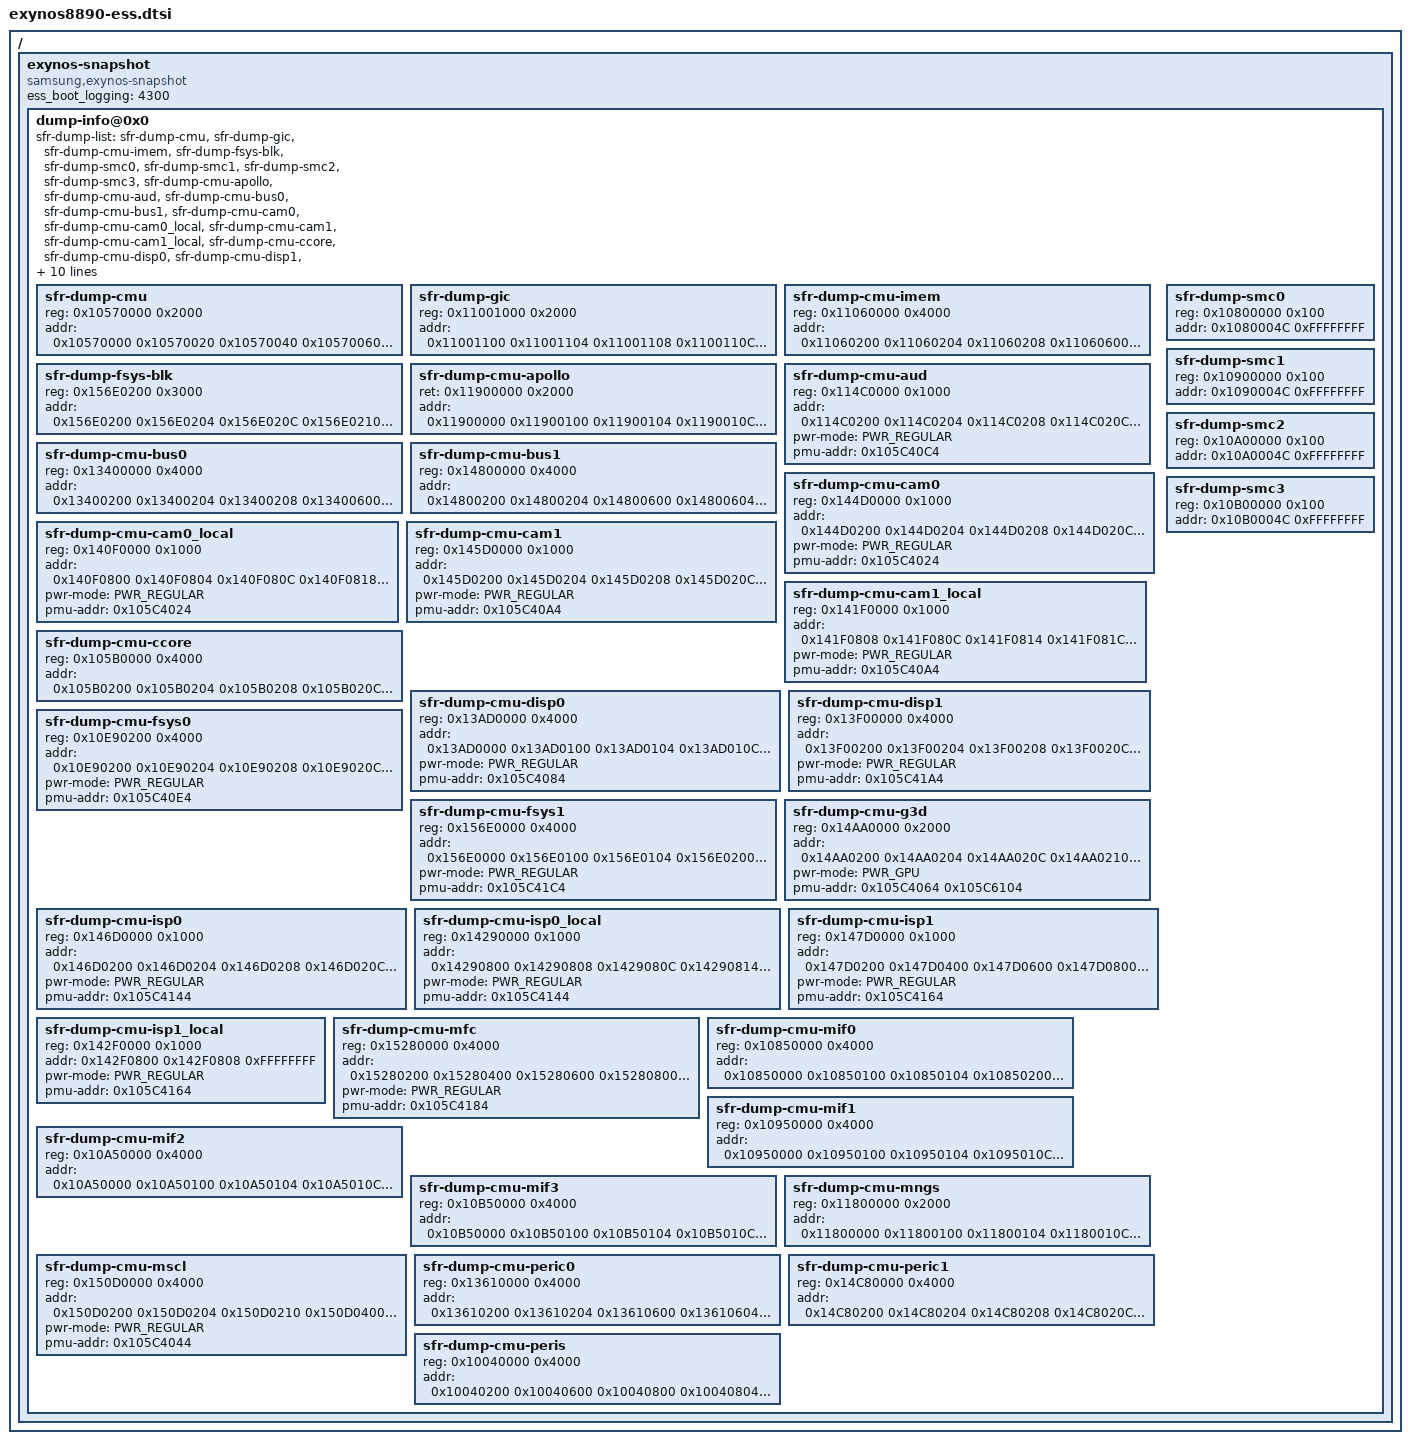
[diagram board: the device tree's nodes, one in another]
/*
 * SAMSUNG EXYNOS8890 SoC device tree source
 *
 * Copyright (c) 2015 Samsung Electronics Co., Ltd.
 *		http://www.samsung.com
 *
 * SAMSUNG EXYNOS8890 SoC device nodes are listed in this file.
 * EXYNOS8890 based board files can include this file and provide
 * values for board specfic bindings.
 *
 * This program is free software; you can redistribute it and/or modify
 * it under the terms of the GNU General Public License version 2 as
 * published by the Free Software Foundation.
 */

/ {
	exynos-snapshot {
		#define PWR_NONE	0
		#define PWR_REGULAR	1
		#define PWR_GPU		2

		compatible = "samsung,exynos-snapshot";
		ess_boot_logging = <4300>;
		dump-info@0x0 {
			sfr-dump-list = "sfr-dump-cmu", "sfr-dump-gic", "sfr-dump-cmu-imem","sfr-dump-fsys-blk",
					"sfr-dump-smc0", "sfr-dump-smc1", "sfr-dump-smc2", "sfr-dump-smc3",
					"sfr-dump-cmu-apollo", "sfr-dump-cmu-aud", "sfr-dump-cmu-bus0", "sfr-dump-cmu-bus1", "sfr-dump-cmu-cam0",
					"sfr-dump-cmu-cam0_local", "sfr-dump-cmu-cam1", "sfr-dump-cmu-cam1_local", "sfr-dump-cmu-ccore", "sfr-dump-cmu-disp0",
					"sfr-dump-cmu-disp1", "sfr-dump-cmu-fsys0", "sfr-dump-cmu-fsys1", "sfr-dump-cmu-g3d", "sfr-dump-cmu-isp0",
					"sfr-dump-cmu-isp0_local", "sfr-dump-cmu-isp1", "sfr-dump-cmu-isp1_local", "sfr-dump-cmu-mfc", "sfr-dump-cmu-mif0",
					"sfr-dump-cmu-mif1", "sfr-dump-cmu-mif2", "sfr-dump-cmu-mif3", "sfr-dump-cmu-mngs", "sfr-dump-cmu-mscl",
					"sfr-dump-cmu-peric0", "sfr-dump-cmu-peric1", "sfr-dump-cmu-peris";
			#address-cells = <1>;
			#size-cells = <1>;

			pmu-regs = <0x105C4000 0x4000>;

			sfr-dump-cmu {
					reg = <0x10570000 0x2000>;
					addr = <0x10570000 0x10570020 0x10570040 0x10570060 0x10570080 0x105700A0 0x105700C0
						0x105700E0 0x10570100 0x10570104 0x1057010C 0x10570120 0x10570124 0x1057012C
						0x10570140 0x10570144 0x1057014C 0x10570160 0x10570164 0x1057016C 0x10570180
						0x10570184 0x1057018C 0x105701A0 0x105701A4 0x105701AC 0x105701C0 0x105701C4
						0x105701C8 0x105701E0 0x105701E4 0x105701EC 0x10570200 0x10570204 0x10570208
						0x1057020C 0x10570210 0x10570214 0x10570218 0x1057021C 0x10570220 0x10570224
						0x10570228 0x1057022C 0x10570230 0x10570234 0x10570240 0x10570244 0x10570248
						0x1057024C 0x10570250 0x10570254 0x10570258 0x1057025C 0x10570260 0x10570264
						0x10570268 0x1057026C 0x10570270 0x10570274 0x10570278 0x1057027C 0x10570280
						0x10570284 0x10570288 0x1057028C 0x10570290 0x10570294 0x10570298 0x1057029C
						0x105702A0 0x105702A4 0x105702A8 0x105702AC 0x105702B0 0x105702B4 0x105702B8
						0x105702BC 0x105702C0 0x105702C4 0x105702C8 0x105702CC 0x105702D0 0x105702D4
						0x105702D8 0x105702DC 0x105702E0 0x105702E4 0x105702E8 0x105702EC 0x105702F0
						0x105702F4 0x105702F8 0x105702FC 0x10570300 0x10570304 0x10570308 0x1057030C
						0x10570310 0x10570314 0x10570318 0x1057031C 0x10570320 0x10570324 0x10570328
						0x1057032C 0x10570330 0x10570334 0x10570338 0x1057033C 0x10570340 0x10570344
						0x10570348 0x1057034C 0x10570350 0x10570354 0x10570358 0x1057035C 0x10570360
						0x10570364 0x10570368 0x1057036C 0x10570370 0x10570374 0x10570378 0x10570380
						0x10570384 0x10570388 0x1057038C 0x10570390 0x105703A0 0x105703A4 0x105703A8
						0x105703AC 0x105703B0 0x105703B4 0x105703B8 0x105703BC 0x105703C0 0x105703C4
						0x105703C8 0x105703CC 0x105703D0 0x105703D4 0x105703D8 0x105703DC 0x105703E0
						0x105703E4 0x105703E8 0x105703EC 0x105703F0 0x105703F4 0x105703F8 0x105703FC
						0x10570400 0x10570404 0x10570408 0x1057040C 0x10570410 0x10570414 0x10570418
						0x1057041C 0x10570420 0x10570424 0x10570428 0x1057042C 0x10570430 0x10570434
						0x10570438 0x1057043C 0x10570440 0x10570444 0x10570448 0x1057044C 0x10570450
						0x10570454 0x10570458 0x1057045C 0x10570460 0x10570464 0x10570468 0x1057046C
						0x10570470 0x10570474 0x10570478 0x1057047C 0x10570480 0x10570484 0x10570488
						0x1057048C 0x10570490 0x10570494 0x10570498 0x1057049C 0x105704A0 0x105704A4
						0x105704A8 0x105704AC 0x105704B0 0x105704B4 0x105704B8 0x105704BC 0x105704C0
						0x105704C4 0x105704C8 0x105704CC 0x105704D0 0x105704D4 0x105704D8 0x105704DC
						0x105704F0 0x105704F4 0x105704F8 0x105704FC 0x10570500 0x10570504 0x10570508
						0x1057050C 0x10570510 0x10570514 0x10570518 0x1057051C 0x10570520 0x10570524
						0x10570528 0x1057052C 0x10570530 0x10570534 0x10570540 0x10570544 0x10570548
						0x1057054C 0x10570550 0x10570554 0x10570558 0x1057055C 0x10570560 0x10570564
						0x10570568 0x1057056C 0x10570570 0x10570574 0x10570578 0x1057057C 0x10570580
						0x10570584 0x10570588 0x1057058C 0x10570590 0x10570594 0x10570598 0x1057059C
						0x105705A0 0x105705A4 0x105705A8 0x105705AC 0x105705B0 0x105705B4 0x105705B8
						0x105705BC 0x105705C0 0x105705C4 0x105705C8 0x105705CC 0x105705D0 0x105705D4
						0x105705D8 0x105705DC 0x105705E0 0x105705E4 0x105705E8 0x105705EC 0x105705F0
						0x105705F4 0x105705F8 0x105705FC 0x10570600 0x10570604 0x10570608 0x1057060C
						0x10570610 0x10570614 0x10570618 0x1057061C 0x10570620 0x10570624 0x10570628
						0x1057062C 0x10570630 0x10570634 0x10570638 0x1057063C 0x10570640 0x10570644
						0x10570648 0x1057064C 0x10570650 0x10570654 0x10570658 0x1057065C 0x10570660
						0x10570664 0x10570668 0x1057066C 0x10570670 0x10570674 0x10570678 0x10570680
						0x10570684 0x10570688 0x1057068C 0x10570690 0x10570800 0x10570804 0x10570808
						0x1057080C 0x10570810 0x10570814 0x10570818 0x1057081C 0x10570820 0x10570824
						0x10570828 0x1057082C 0x10570830 0x10570834 0x10570838 0x1057083C 0x10570840
						0x10570844 0x10570848 0x1057084C 0x10570850 0x10570854 0x10570858 0x1057085C
						0x10570860 0x10570864 0x10570868 0x1057086C 0x10570870 0x10570874 0x10570878
						0x1057087C 0x10570880 0x10570884 0x10570888 0x1057088C 0x10570890 0x10570894
						0x10570898 0x1057089C 0x105708A0 0x105708A4 0x105708A8 0x105708AC 0x105708B0
						0x10570900 0x10570904 0x10570908 0x1057090C 0x10570910 0x10570914 0x10570918
						0x1057091C 0x10570920 0x10570924 0x10570928 0x1057092C 0x10570930 0x10570934
						0x10570938 0x1057093C 0x10570940 0x10570944 0x10570948 0x1057094C 0x10570950
						0x10570954 0x10570958 0x1057095C 0x10570960 0x10570964 0x10570968 0x1057096C
						0x10570970 0x10570974 0x10570978 0x1057097C 0x10570980 0x10570984 0x10570990
						0x10570994 0x10570998 0x1057099C 0x105709A0 0x10570B00 0x10570B04 0x10570B08
						0x10570B0C 0x10570B10 0x10570B14 0x10570B18 0x10570B1C 0x10570B20 0x10570B24
						0x10570B28 0x10570B2C 0x10570B30 0x10570B34 0x10570B38 0x10570B3C 0x10570B40
						0x10570B44 0x10570B48 0x10570B4C 0x10570B50 0x10570B54 0x10570B58 0x10570B5C
						0x10570C00 0x10570C04 0x10570C10 0x10570C14 0x10570C20 0x10570C24 0x10570C30
						0x10570C34 0x10570C38 0x10570C3C 0x10570D00 0x10570D0C 0x10570D10 0x10570E00
						0x10570F04 0x10570F10 0x10570F14 0x10570F18 0x10570F1C 0x10570F20 0x10570F24
						0x10570F28 0x10570F2C 0x10570F30 0x10570F40 0x10570F44 0x10570F48 0x10570F4C
						0x10570F50 0x10570F54 0x10570F58 0x10570F5C 0x10570F60 0x10570F80 0x10571000
						0x10571004 0x10571008 0x1057100C 0x10571010 0x10571014 0x10571018 0x1057101C
						0x10571020 0x10571024 0x10571028 0x1057102C 0x10571030 0x10571034 0x10571060
						0x10571080 0x10571084 0x10571088 0x1057108C 0x10571090 0x10571094 0x10571098
						0x1057109C 0x10571100 0x10571104 0x10571108 0x1057110C 0xFFFFFFFF>;
			};

			sfr-dump-gic {
					reg = <0x11001000 0x2000>;
					addr = <0x11001100 0x11001104 0x11001108 0x1100110C 0x11001110 0x11001114 0x11001118 0x1100111C
						0x11001120 0x11001124 0x11001128 0x1100112C 0x11001130 0x11001134 0x11001138 0x1100113C
						0x11001200 0x11001204 0x11001208 0x1100120C 0x11001210 0x11001214 0x11001218 0x1100121C
						0x11001220 0x11001224 0x11001228 0x1100122C 0x11001230 0x11001234 0x11001238 0x1100123C
						0x11001300 0x11001304 0x11001308 0x1100130C 0x11001310 0x11001314 0x11001318 0x1100131C
						0x11001320 0x11001324 0x11001328 0x1100132C 0x11001330 0x11001334 0x11001338 0x1100133C
						0xFFFFFFFF>;
			};

			sfr-dump-cmu-imem {
					reg = <0x11060000 0x4000>;
					addr = <0x11060200 0x11060204 0x11060208 0x11060600 0x11060604 0x11060608 0x11060800
						0x11060804 0x11060808 0x1106080C 0x11060810 0x11060814 0x11060818 0x1106081C
						0x11060820 0x11060C00 0x11060C04 0x11060C08 0x11060C0C 0x11060D04 0x11061800
						0x11061804 0x11061808 0x1106180C 0x11061810 0x11061814 0x11061818 0x1106181C
						0x11061820 0x11061C00 0x11061C04 0x11061C08 0x11061C0C 0x11061C10 0x11061C14
						0x11061C18 0x11061C1C 0x11061C20 0x11061C24 0x11061C28 0x11061C2C 0x11062000
						0x11062004 0x11062008 0x1106200C 0x11062010 0x11062014 0x11062018 0x1106201C
						0x11062020 0x11062024 0x11062028 0x1106202C 0x11062030 0x11062400 0x11062408
						0xFFFFFFFF>;
			};

			sfr-dump-fsys-blk {
					reg = <0x156E0200 0x3000>;
					addr = <0x156E0200 0x156E0204 0x156E020C 0x156E0210 0x156E0214 0x156E0218 0x156E0220 0x156E0224
						0x156E0230 0x156E0234 0x156E0238 0x156E023C 0x156E0240 0x156E0244 0x156E0400 0x156E0630
						0x156E0634 0x156E0638 0x156E063C 0x156E0640 0x156E0644 0x156E1800 0x156E1824 0x156E1844
						0x156E1848 0x156E184C 0x156E185C 0x156E1860 0x156E186C 0x156E1870 0x156E1874 0x156E1878
						0x156E187C 0x156E1880 0x156E1C00 0x156E1C04 0x156E1C08 0x156E1C0C 0x156E1C10 0x156E1C24
						0x156E1C44 0x156E1C48 0x156E1C4C 0x156E1C5C 0x156E1C60 0x156E1C6C 0x156E1C70 0x156E1C74
						0x156E1C78 0x156E1C7C 0x156E1C80 0x156E2000 0x156E2004 0x156E2008 0x156E200C 0x156E2010
						0x156E2014 0x156E2018 0x156E201C 0x156E2020 0x156E2024 0x156E2028 0x156E202C 0x156E241C
						0x156E2420 0x156E2424 0x156E2428 0x156E242C 0x156E2430 0x156E2434 0x156E2438 0x156E243C
						0x156E2440 0x156E2444 0xFFFFFFFF>;
 			};

			sfr-dump-cmu-apollo {
					ret = <0x11900000 0x2000>;
					addr = <0x11900000 0x11900100 0x11900104 0x1190010C 0x11900200 0x11900204 0x11900208 0x11900400 0x11900404 0x11900408
						0x1190040C 0x11900410 0x11900414 0x11900418 0x1190041C 0x11900420 0x11900600 0x11900604 0x11900608 0x11900800
						0x11900804 0x11900900 0x11900904 0x11900908 0x11900A00 0x11900A04 0x11900C00 0x11900C04 0x11900D00 0x11900D04
						0x11900D08 0x11900D0C 0x11901000 0x11901020 0x11901024 0x11901028 0x1190102C 0x11901080 0x11901084 0x11901088
						0xFFFFFFFF>;
			};

			sfr-dump-cmu-aud {
					reg = <0x114C0000 0x1000>;
					addr = <0x114C0200 0x114C0204 0x114C0208 0x114C020C 0x114C0210 0x114C0214 0x114C0400 0x114C0404 0x114C0408 0x114C040C
						0x114C0410 0x114C0414 0x114C0418 0x114C041C 0x114C0424 0x114C0428 0x114C042C 0x114C0430 0x114C0600 0x114C060C
						0x114C0610 0x114C0614 0x114C0800 0x114C0804 0x114C0808 0x114C080C 0x114C0810 0x114C0814 0x114C0818 0x114C081C
						0x114C0820 0x114C0824 0x114C0828 0x114C0D00 0x114C0D04 0x114C0D08 0x114C0D0C 0x114C0E00 0x114C0F28 0xFFFFFFFF>;
					pwr-mode = <PWR_REGULAR>;
					pmu-addr = <0x105C40C4>;	/* AUD_STATUS */
			};

			sfr-dump-cmu-bus0 {
					reg = <0x13400000 0x4000>;
					addr = <0x13400200 0x13400204 0x13400208 0x13400600 0x13400604 0x13400608 0x13400800 0x13400804 0x13400900 0x13400D00
						0x13400D04 0x13400D08 0x13400D0C 0x13400E00 0x13400F28 0x13401800 0x13401804 0x13401900 0x13401C00 0x13401C04
						0x13401C08 0x13401D00 0x13401D04 0x13401D08 0x13402000 0x13402004 0x13402008 0x1340200C 0x13402010 0x13402014
						0x1340201C 0x13402020 0x13402024 0x13402100 0x13402104 0x13402108 0x1340210C 0x13402110 0x13402114 0x13402118
						0x1340211C 0x13402120 0x13402124 0x13402128 0x1340212C 0xFFFFFFFF>;
			};

			sfr-dump-cmu-bus1 {
					reg = <0x14800000 0x4000>;
					addr = <0x14800200 0x14800204 0x14800600 0x14800604 0x14800800 0x14800900 0x14800D00 0x14800D04 0x14800D08 0x14800D0C
						0x14800F28 0x14801800 0x14801900 0x14801C00 0x14801D00 0x14801D04 0x14802000 0x14802004 0x14802008 0x1480200C
						0x14802010 0x14802014 0x14802018 0x1480201C 0x14802020 0x14802024 0x14802028 0x1480202C 0x14802030 0xFFFFFFFF>;
			};

			sfr-dump-cmu-cam0 {
					reg = <0x144D0000 0x1000>;
					addr = <0x144D0200 0x144D0204 0x144D0208 0x144D020C 0x144D0214 0x144D0218 0x144D021C 0x144D0220 0x144D0224 0x144D0228
						0x144D022C 0x144D0230 0x144D0234 0x144D0400 0x144D040C 0x144D0410 0x144D0414 0x144D0418 0x144D0600 0x144D0604
						0x144D0608 0x144D060C 0x144D0614 0x144D0618 0x144D061C 0x144D0620 0x144D0624 0x144D0628 0x144D062C 0x144D0630
						0x144D0634 0x144D0800 0x144D0804 0x144D080C 0x144D0818 0x144D081C 0x144D0828 0x144D082C 0x144D0830 0x144D0834
						0x144D0838 0x144D083C 0x144D0840 0x144D0844 0x144D0848 0x144D084C 0x144D0850 0x144D0854 0x144D0858 0x144D085C
						0x144D0860 0x144D0D00 0x144D0D04 0x144D0D08 0x144D0D0C 0x144D0E00 0x144D0F28 0xFFFFFFFF>;
					pwr-mode = <PWR_REGULAR>;
					pmu-addr = <0x105C4024>;	/* CAM0_STATUS */
			};

			sfr-dump-cmu-cam0_local {
					reg = <0x140F0000 0x1000>;
					addr = <0x140F0800 0x140F0804 0x140F080C 0x140F0818 0x140F081C 0x140F0828 0x140F082C 0x140F0830 0x140F0834 0x140F083C
						0xFFFFFFFF>;
					pwr-mode = <PWR_REGULAR>;
					pmu-addr = <0x105C4024>;	/* CAM0_STATUS */
			};

			sfr-dump-cmu-cam1 {
					reg = <0x145D0000 0x1000>;
					addr = <0x145D0200 0x145D0204 0x145D0208 0x145D020C 0x145D0210 0x145D0214 0x145D0218 0x145D021C 0x145D0220 0x145D0224
						0x145D0228 0x145D022C 0x145D0230 0x145D0234 0x145D0238 0x145D023C 0x145D0400 0x145D0408 0x145D040C 0x145D0600
						0x145D0604 0x145D0608 0x145D060C 0x145D0610 0x145D0614 0x145D0618 0x145D061C 0x145D0620 0x145D0624 0x145D0628
						0x145D062C 0x145D0630 0x145D0634 0x145D0638 0x145D063C 0x145D0800 0x145D0804 0x145D0808 0x145D080C 0x145D0810
						0x145D0814 0x145D0818 0x145D081C 0x145D0820 0x145D0828 0x145D0830 0x145D083C 0x145D0840 0x145D0844 0x145D0848
						0x145D084C 0x145D0850 0x145D0854 0x145D0858 0x145D085C 0x145D0860 0x145D0D00 0x145D0D04 0x145D0D08 0x145D0D0C
						0x145D0E00 0x145D0F28 0xFFFFFFFF>;
					pwr-mode = <PWR_REGULAR>;
					pmu-addr = <0x105C40A4>;	/* CAM1_STATUS */
			};

			sfr-dump-cmu-cam1_local {
					reg = <0x141F0000 0x1000>;
					addr = <0x141F0808 0x141F080C 0x141F0814 0x141F081C 0x141F0820 0x141F0828 0x141F0830 0xFFFFFFFF>;
					pwr-mode = <PWR_REGULAR>;
					pmu-addr = <0x105C40A4>;	/* CAM1_STATUS */
			};

			sfr-dump-cmu-ccore {
					reg = <0x105B0000 0x4000>;
					addr = <0x105B0200 0x105B0204 0x105B0208 0x105B020C 0x105B0210 0x105B0214 0x105B0400 0x105B0500 0x105B0504 0x105B0508
						0x105B050C 0x105B0510 0x105B0514 0x105B0800 0x105B0804 0x105B0808 0x105B080C 0x105B0810 0x105B0814 0x105B0818
						0x105B0900 0x105B0904 0x105B0A00 0x105B0C00 0x105B0C04 0x105B0E00 0x105B0F28 0x105B1000 0x105B1004 0x105B1800
						0x105B1804 0x105B1808 0x105B180C 0x105B1810 0x105B1814 0x105B1818 0x105B1900 0x105B1904 0x105B1A00 0x105B1C00
						0x105B1C04 0x105B1C08 0x105B1C0C 0x105B1C10 0x105B1C14 0x105B1C18 0x105B1C1C 0x105B1C20 0x105B1C24 0x105B1C28
						0x105B1C2C 0x105B1D00 0x105B1D04 0x105B1E00 0x105B2000 0x105B2004 0x105B2000 0x105B2004 0x105B2008 0x105B200C
						0x105B2010 0x105B2014 0x105B2018 0x105B201C 0x105B2020 0x105B2024 0x105B2028 0x105B202C 0x105B2030 0x105B2034
						0x105B2038 0x105B203C 0x105B2040 0x105B2044 0x105B2048 0x105B2400 0x105B2404 0x105B2408 0x105B240C 0x105B2410
						0x105B2414 0x105B2418 0x105B241C 0x105B2420 0x105B2424 0xFFFFFFFF>;
			};

			sfr-dump-cmu-disp0 {
					reg = <0x13AD0000 0x4000>;
					addr = <0x13AD0000 0x13AD0100 0x13AD0104 0x13AD010C 0x13AD0200 0x13AD0204 0x13AD0208 0x13AD020C 0x13AD0210 0x13AD0214
						0x13AD0218 0x13AD021C 0x13AD0220 0x13AD0224 0x13AD0228 0x13AD022C 0x13AD0230 0x13AD0234 0x13AD0238 0x13AD023C
						0x13AD0240 0x13AD0244 0x13AD0248 0x13AD024C 0x13AD0250 0x13AD0254 0x13AD0258 0x13AD025C 0x13AD0260 0x13AD0264
						0x13AD0268 0x13AD0400 0x13AD0404 0x13AD0408 0x13AD040C 0x13AD0410 0x13AD0414 0x13AD0500 0x13AD0504 0x13AD0600
						0x13AD0604 0x13AD0608 0x13AD060C 0x13AD0610 0x13AD0614 0x13AD0618 0x13AD061C 0x13AD0620 0x13AD0624 0x13AD0628
						0x13AD062C 0x13AD0630 0x13AD0634 0x13AD0638 0x13AD063C 0x13AD0640 0x13AD0644 0x13AD0648 0x13AD064C 0x13AD0650
						0x13AD0654 0x13AD0658 0x13AD065C 0x13AD0660 0x13AD0664 0x13AD0668 0x13AD0800 0x13AD0804 0x13AD0808 0x13AD080C
						0x13AD0820 0x13AD0824 0x13AD0828 0x13AD082C 0x13AD0830 0x13AD0834 0x13AD0840 0x13AD0844 0x13AD0848 0x13AD084C
						0x13AD0850 0x13AD0854 0x13AD0858 0x13AD085C 0x13AD0860 0x13AD0864 0x13AD0868 0x13AD086C 0x13AD0C00 0x13AD0C04
						0x13AD0D04 0x13AD0D08 0x13AD0D0C 0x13AD1800 0x13AD1804 0x13AD1808 0x13AD180C 0x13AD1820 0x13AD1824 0x13AD1828
						0x13AD182C 0x13AD1830 0x13AD1834 0x13AD1840 0x13AD1844 0x13AD1848 0x13AD184C 0x13AD1850 0x13AD1854 0x13AD1858
						0x13AD185C 0x13AD1860 0x13AD1864 0x13AD1868 0x13AD186C 0x13AD1C00 0x13AD1C04 0x13AD1C08 0x13AD1C0C 0x13AD1C20
						0x13AD1C24 0x13AD1C28 0x13AD1C2C 0x13AD1C30 0x13AD1C34 0x13AD1C38 0x13AD1C3C 0x13AD1C40 0x13AD1C44 0x13AD1C48
						0x13AD1C4C 0x13AD1C50 0x13AD1C54 0x13AD1C58 0x13AD1C5C 0x13AD1C60 0x13AD1C64 0x13AD1C68 0x13AD1C6C 0x13AD2000
						0x13AD2004 0x13AD2008 0x13AD200C 0x13AD2010 0x13AD2014 0x13AD2018 0x13AD2020 0x13AD2024 0x13AD2028 0x13AD202C
						0x13AD2030 0x13AD2034 0x13AD203C 0x13AD2040 0x13AD2044 0x13AD2048 0x13AD204C 0x13AD2050 0x13AD2054 0x13AD240C
						0x13AD2410 0x13AD2414 0x13AD2418 0x13AD241C 0x13AD2420 0x13AD2424 0x13AD2428 0x13AD2434 0x13AD2438 0x13AD2444
						0x13AD2448 0x13AD2484 0x13AD2488 0x13AD248C 0x13AD2490 0xFFFFFFFF>;
					pwr-mode = <PWR_REGULAR>;
					pmu-addr = <0x105C4084>;	/* DISP0_STATUS */
			};

			sfr-dump-cmu-disp1 {
					reg = <0x13F00000 0x4000>;
					addr = <0x13F00200 0x13F00204 0x13F00208 0x13F0020C 0x13F00210 0x13F00214 0x13F00218 0x13F0021C 0x13F00220 0x13F00224
						0x13F00228 0x13F0022C 0x13F00230 0x13F00400 0x13F00404 0x13F00408 0x13F00600 0x13F00604 0x13F00608 0x13F0060C
						0x13F00610 0x13F00614 0x13F00618 0x13F0061C 0x13F00620 0x13F00624 0x13F00628 0x13F0062C 0x13F00630 0x13F00800
						0x13F00804 0x13F00808 0x13F0080C 0x13F00820 0x13F00824 0x13F00828 0x13F0082C 0x13F00840 0x13F00844 0x13F00848
						0x13F00C00 0x13F00C04 0x13F00D04 0x13F00D08 0x13F00D0C 0x13F01800 0x13F01804 0x13F01808 0x13F0180C 0x13F01820
						0x13F01824 0x13F01828 0x13F0182C 0x13F01840 0x13F01844 0x13F01848 0x13F01C00 0x13F01C04 0x13F01C08 0x13F01C0C
						0x13F01C20 0x13F01C24 0x13F01C28 0x13F01C2C 0x13F01C30 0x13F01C34 0x13F01C40 0x13F01C44 0x13F01C48 0x13F02000
						0x13F02004 0x13F02008 0x13F0200C 0x13F02010 0x13F02014 0x13F0201C 0x13F02020 0x13F02028 0x13F0202C 0x13F02030
						0x13F02034 0x13F02038 0x13F0203C 0x13F02040 0x13F02044 0x13F0240C 0x13F02410 0x13F0241C 0x13F02420 0xFFFFFFFF>;
					pwr-mode = <PWR_REGULAR>;
					pmu-addr = <0x105C41A4>;	/* DISP1_STATUS */
			};

			sfr-dump-cmu-fsys0 {
					reg = <0x10E90200 0x4000>;
					addr = <0x10E90200 0x10E90204 0x10E90208 0x10E9020C 0x10E90210 0x10E90214 0x10E90218 0x10E9021C 0x10E90220 0x10E90224
						0x10E90228 0x10E90234 0x10E90600 0x10E90604 0x10E90608 0x10E9060C 0x10E90610 0x10E90614 0x10E90618 0x10E9061C
						0x10E90620 0x10E90624 0x10E90628 0x10E90634 0x10E90800 0x10E90820 0x10E90840 0x10E90844 0x10E90848 0x10E9084C
						0x10E90850 0x10E90854 0x10E90858 0x10E9085C 0x10E90860 0x10E90864 0x10E90878 0x10E9087C 0x10E90880 0x10E90C00
						0x10E90C04 0x10E90D04 0x10E90D08 0x10E90D0C 0x10E91800 0x10E91820 0x10E91840 0x10E91844 0x10E91848 0x10E9184C
						0x10E91850 0x10E91854 0x10E91858 0x10E9185C 0x10E91860 0x10E91864 0x10E91878 0x10E9187C 0x10E91880 0x10E91C00
						0x10E91C04 0x10E91C08 0x10E91C0C 0x10E91C20 0x10E91C40 0x10E91C44 0x10E91C48 0x10E91C4C 0x10E91C50 0x10E91C54
						0x10E91C58 0x10E91C5C 0x10E91C60 0x10E91C64 0x10E91C78 0x10E91C7C 0x10E91C80 0x10E92000 0x10E92004 0x10E92008
						0x10E9200C 0x10E92010 0x10E92014 0x10E92018 0x10E9201C 0x10E92020 0x10E92024 0x10E92028 0x10E9202C 0x10E92034
						0x10E92038 0x10E9203C 0x10E92040 0x10E92044 0x10E92400 0x10E92404 0x10E92408 0x10E9240C 0x10E92410 0x10E92414
						0x10E92418 0xFFFFFFFF>;
					pwr-mode = <PWR_REGULAR>;
					pmu-addr = <0x105C40E4>;	/* FSYS0_STATUS */
			};

			sfr-dump-cmu-fsys1 {
					reg = <0x156E0000 0x4000>;
					addr = <0x156E0000 0x156E0100 0x156E0104 0x156E0200 0x156E0204 0x156E020C 0x156E0210 0x156E0214 0x156E0218 0x156E0220
						0x156E0224 0x156E0230 0x156E0234 0x156E0238 0x156E023C 0x156E0240 0x156E0244 0x156E0400 0x156E0600 0x156E0604
						0x156E060C 0x156E0610 0x156E0614 0x156E0618 0x156E0620 0x156E0624 0x156E0630 0x156E0634 0x156E0638 0x156E063C
						0x156E0640 0x156E0644 0x156E0800 0x156E0820 0x156E0824 0x156E0840 0x156E0844 0x156E0848 0x156E084C 0x156E085C
						0x156E0860 0x156E086C 0x156E0870 0x156E0874 0x156E0878 0x156E087C 0x156E0880 0x156E0890 0x156E0C00 0x156E0C04
						0x156E0D04 0x156E1800 0x156E1820 0x156E1824 0x156E1840 0x156E1844 0x156E1848 0x156E184C 0x156E185C 0x156E1860
						0x156E186C 0x156E1870 0x156E1874 0x156E1878 0x156E187C 0x156E1880 0x156E1890 0x156E1C00 0x156E1C04 0x156E1C08
						0x156E1C0C 0x156E1C10 0x156E1C20 0x156E1C24 0x156E1C40 0x156E1C44 0x156E1C48 0x156E1C4C 0x156E1C5C 0x156E1C60
						0x156E1C6C 0x156E1C70 0x156E1C74 0x156E1C78 0x156E1C7C 0x156E1C80 0x156E1C90 0x156E2000 0x156E2004 0x156E2008
						0x156E200C 0x156E2010 0x156E2014 0x156E2018 0x156E201C 0x156E2020 0x156E2024 0x156E2028 0x156E202C 0x156E241C
						0x156E2420 0x156E2424 0x156E2428 0x156E242C 0x156E2430 0x156E2434 0x156E2438 0x156E243C 0x156E2440 0x156E2444
						0xFFFFFFFF>;
					pwr-mode = <PWR_REGULAR>;
					pmu-addr = <0x105C41C4>;	/* FSYS1_STATUS */
			};

			sfr-dump-cmu-g3d {
					reg = <0x14AA0000 0x2000>;
					addr = <0x14AA0200 0x14AA0204 0x14AA020C 0x14AA0210 0x14AA0214 0x14AA0400 0x14AA0404 0x14AA0408 0x14AA040C 0x14AA0600
						0x14AA0604 0x14AA060C 0x14AA0610 0x14AA0614 0x14AA0800 0x14AA0804 0x14AA0900 0x14AA0A00 0x14AA0A04 0x14AA0C00
						0x14AA0C04 0x14AA0E00 0x14AA0F28 0x14AA1000 0x14AA1100 0x14AA1104 0xFFFFFFFF>;
					pwr-mode = <PWR_GPU>;
					pmu-addr = <0x105C4064 0x105C6104>;	/* G3D_STATUS, GPU_DVS_STATUS */
			};

			sfr-dump-cmu-isp0 {
					reg = <0x146D0000 0x1000>;
					addr = <0x146D0200 0x146D0204 0x146D0208 0x146D020C 0x146D0400 0x146D0404 0x146D0408 0x146D040C 0x146D0600 0x146D0604
						0x146D0608 0x146D060C 0x146D0800 0x146D0808 0x146D080C 0x146D0814 0x146D0818 0x146D081C 0x146D0820 0x146D0824
						0x146D0828 0x146D082C 0x146D0D00 0x146D0D04 0x146D0D08 0x146D0D0C 0x146D0E00 0x146D0E04 0xFFFFFFFF>;
					pwr-mode = <PWR_REGULAR>;
					pmu-addr = <0x105C4144>;	/* ISP0_STATUS */
			};

			sfr-dump-cmu-isp0_local {
					reg = <0x14290000 0x1000>;
					addr = <0x14290800 0x14290808 0x1429080C 0x14290814 0x14290818 0x14290824 0x14290828 0xFFFFFFFF>;
					pwr-mode = <PWR_REGULAR>;
					pmu-addr = <0x105C4144>;	/* ISP0_STATUS */
			};

			sfr-dump-cmu-isp1 {
					reg = <0x147D0000 0x1000>;
					addr = <0x147D0200 0x147D0400 0x147D0600 0x147D0800 0x147D0808 0x147D080C 0x147D0810 0x147D0D00 0x147D0D04 0x147D0D08
						0x147D0D0C 0x147D0E00 0x147D0E04 0xFFFFFFFF>;
					pwr-mode = <PWR_REGULAR>;
					pmu-addr = <0x105C4164>;	/* ISP1_STATUS */
			};

			sfr-dump-cmu-isp1_local {
					reg = <0x142F0000 0x1000>;
					addr = <0x142F0800 0x142F0808 0xFFFFFFFF>;
					pwr-mode = <PWR_REGULAR>;
					pmu-addr = <0x105C4164>;	/* ISP1_STATUS */
			};

			sfr-dump-cmu-mfc {
					reg = <0x15280000 0x4000>;
					addr = <0x15280200 0x15280400 0x15280600 0x15280800 0x15280804 0x15280808 0x15280820 0x15280824 0x15280828 0x1528082C
						0x15280840 0x15280C00 0x15280C04 0x15280D04 0x15280D08 0x15280D0C 0x15281800 0x15281804 0x15281808 0x15281820
						0x15281824 0x15281828 0x1528182C 0x15281840 0x15281C00 0x15281C04 0x15281C08 0x15281C20 0x15281C24 0x15281C28
						0x15281C2C 0x15281C30 0x15281C40 0x15282000 0x15282004 0x15282008 0x1528200C 0x15282010 0x15282014 0x15282018
						0x1528201C 0x15282020 0x15282024 0x15282028 0x1528202C 0x15282030 0x15282404 0x15282408 0xFFFFFFFF>;
					pwr-mode = <PWR_REGULAR>;
					pmu-addr = <0x105C4184>;	/* MFC_STATUS */
			};

			sfr-dump-cmu-mif0 {
					reg = <0x10850000 0x4000>;
					addr = <0x10850000 0x10850100 0x10850104 0x10850200 0x10850200 0x10850204 0x10850208 0x10850210 0x10850214 0x10850218
						0x10850400 0x10850404 0x10850408 0x10850600 0x10850604 0x10850608 0x10850610 0x10850614 0x10850618 0x10850900
						0x10850A00 0x10850A04 0x10850A08 0x10850C00 0x10850C04 0x10850F28 0x10850F28 0x10851000 0x10851004 0x10851100
						0x10851104 0x10851900 0x10851A00 0x10851A04 0x10851A08 0x10851D00 0x10851D04 0x10851E00 0x10851E04 0x10851E08
						0x10852000 0x10852004 0x10852008 0x1085200C 0x10852010 0x10852400 0x10852404 0xFFFFFFFF>;
			};

			sfr-dump-cmu-mif1 {
					reg = <0x10950000 0x4000>;
					addr = <0x10950000 0x10950100 0x10950104 0x1095010C 0x10950200 0x10950204 0x10950208 0x10950210 0x10950214 0x10950218
						0x10950400 0x10950404 0x10950408 0x10950600 0x10950604 0x10950608 0x10950610 0x10950614 0x10950618 0x10950900
						0x10950A00 0x10950A04 0x10950A08 0x10950C00 0x10950C04 0x10950E00 0x10950F28 0x10951000 0x10951004 0x10951100
						0x10951104 0x10951900 0x10951A00 0x10951A04 0x10951A08 0x10951D00 0x10951D04 0x10951E00 0x10951E04 0x10951E08
						0x10952000 0x10952004 0x10952008 0x1095200C 0x10952010 0x10952400 0x10952404 0xFFFFFFFF>;
			};

			sfr-dump-cmu-mif2 {
					reg = <0x10A50000 0x4000>;
					addr = <0x10A50000 0x10A50100 0x10A50104 0x10A5010C 0x10A50200 0x10A50204 0x10A50208 0x10A50210 0x10A50214 0x10A50218
						0x10A50400 0x10A50404 0x10A50408 0x10A50600 0x10A50604 0x10A50608 0x10A50610 0x10A50614 0x10A50618 0x10A50900
						0x10A50A00 0x10A50A04 0x10A50A08 0x10A50C00 0x10A50C04 0x10A50E00 0x10A50F28 0x10A51000 0x10A51004 0x10A51100
						0x10A51104 0x10A51900 0x10A51A00 0x10A51A04 0x10A51A08 0x10A51D00 0x10A51D04 0x10A51E00 0x10A51E04 0x10A51E08
						0x10A52000 0x10A52004 0x10A52008 0x10A5200C 0x10A52010 0x10A52400 0x10A52404 0xFFFFFFFF>;
			};

			sfr-dump-cmu-mif3 {
					reg = <0x10B50000 0x4000>;
					addr = <0x10B50000 0x10B50100 0x10B50104 0x10B5010C 0x10B50200 0x10B50204 0x10B50208 0x10B50210 0x10B50214 0x10B50218
						0x10B50400 0x10B50404 0x10B50408 0x10B50600 0x10B50604 0x10B50608 0x10B50610 0x10B50614 0x10B50618 0x10B50900
						0x10B50A00 0x10B50A04 0x10B50A08 0x10B50C00 0x10B50C04 0x10B50E00 0x10B50F28 0x10B51000 0x10B51004 0x10B51100
						0x10B51104 0x10B51900 0x10B51A00 0x10B51A04 0x10B51A08 0x10B51D00 0x10B51D04 0x10B51E00 0x10B51E04 0x10B51E08
						0x10B52000 0x10B52004 0x10B52008 0x10B5200C 0x10B52010 0x10B52400 0x10B52404 0xFFFFFFFF>;
			};

			sfr-dump-cmu-mngs {
					reg = <0x11800000 0x2000>;
					addr = <0x11800000 0x11800100 0x11800104 0x1180010C 0x11800200 0x11800204 0x11800208 0x11800400 0x11800404 0x11800408
						0x1180040C 0x11800410 0x11800414 0x11800418 0x1180041C 0x11800420 0x11800424 0x11800428 0x1180042C 0x11800430
						0x11800434 0x11800600 0x11800604 0x11800608 0x11800800 0x11800804 0x11800808 0x1180080C 0x11800810 0x11800814
						0x11800900 0x11800904 0x11800908 0x11800A00 0x11800A04 0x11800C00 0x11800C04 0x11800D00 0x11800D04 0x11800D08
						0x11800D0C 0x11801000 0x11801020 0x11801024 0x11801028 0x1180102C 0x11801080 0x11801084 0x11801088 0xFFFFFFFF>;
			};

			sfr-dump-cmu-mscl {
					reg = <0x150D0000 0x4000>;
					addr = <0x150D0200 0x150D0204 0x150D0210 0x150D0400 0x150D0600 0x150D0604 0x150D0610 0x150D0800 0x150D0804 0x150D0808
						0x150D080C 0x150D0820 0x150D0824 0x150D0828 0x150D0C00 0x150D0C04 0x150D0D04 0x150D0D08 0x150D0D0C 0x150D1800
						0x150D1804 0x150D1808 0x150D180C 0x150D1820 0x150D1824 0x150D1828 0x150D1C00 0x150D1C04 0x150D1C08 0x150D1C0C
						0x150D1C10 0x150D1C14 0x150D1C20 0x150D1C24 0x150D1C28 0x150D1C2C 0x150D1C30 0x150D2000 0x150D2004 0x150D2008
						0x150D200C 0x150D2010 0x150D2014 0x150D2018 0x150D201C 0x150D2020 0x150D2024 0x150D2028 0x150D202C 0x150D2030
						0x150D2034 0x150D2038 0x150D203C 0x150D2040 0x150D2044 0xFFFFFFFF>;
					pwr-mode = <PWR_REGULAR>;
					pmu-addr = <0x105C4044>;	/* MSCL_STATUS */
			};

			sfr-dump-cmu-peric0 {
					reg = <0x13610000 0x4000>;
					addr = <0x13610200 0x13610204 0x13610600 0x13610604 0x13610800 0x13610840 0x13610844 0x13610C00 0x13610C04 0x13610D04
						0x13610D08 0x13610D0C 0x13611800 0x13611840 0x13611844 0x13611C00 0x13611C04 0x13611C40 0x13611C44 0x13612000
						0x13612004 0x13612008 0x1361200C 0x13612404 0x13612408 0x1361240C 0x13612410 0x13612414 0x13612418 0x1361241C
						0x13612420 0x13612424 0x13612428 0x1361242C 0xFFFFFFFF>;
			};

			sfr-dump-cmu-peric1 {
					reg = <0x14C80000 0x4000>;
					addr = <0x14C80200 0x14C80204 0x14C80208 0x14C8020C 0x14C80210 0x14C80214 0x14C80218 0x14C8021C 0x14C80220 0x14C80224
						0x14C80228 0x14C8022C 0x14C80230 0x14C80234 0x14C80600 0x14C80604 0x14C80608 0x14C8060C 0x14C80610 0x14C80614
						0x14C80618 0x14C8061C 0x14C80620 0x14C80624 0x14C80628 0x14C8062C 0x14C80630 0x14C80634 0x14C80800 0x14C80804
						0x14C80840 0x14C80844 0x14C80848 0x14C8084C 0x14C80850 0x14C80854 0x14C80858 0x14C8085C 0x14C80860 0x14C80864
						0x14C80868 0x14C8086C 0x14C80870 0x14C80C00 0x14C80C04 0x14C80D04 0x14C80D08 0x14C80D0C 0x14C81800 0x14C81804
						0x14C81840 0x14C81844 0x14C81848 0x14C8184C 0x14C81850 0x14C81854 0x14C81858 0x14C8185C 0x14C81860 0x14C81864
						0x14C81868 0x14C8186C 0x14C81870 0x14C81C00 0x14C81C04 0x14C81C08 0x14C81C0C 0x14C81C10 0x14C81C40 0x14C81C44
						0x14C81C48 0x14C81C4C 0x14C81C50 0x14C81C54 0x14C81C58 0x14C81C5C 0x14C81C60 0x14C81C64 0x14C81C68 0x14C81C6C
						0x14C81C70 0x14C82000 0x14C82004 0x14C82008 0x14C8200C 0x14C82410 0x14C82414 0x14C82418 0x14C8241C 0x14C82420
						0x14C82424 0x14C82428 0x14C8242C 0x14C82430 0x14C82434 0x14C82438 0x14C8243C 0x14C82440 0x14C82444 0x14C82448
						0x14C8244C 0x14C82450 0x14C82454 0x14C82458 0x14C8245C 0x14C82460 0x14C82464 0x14C82468 0x14C8246C 0x14C82470
						0x14C82474 0xFFFFFFFF>;
			};

			sfr-dump-cmu-peris {
					reg = <0x10040000 0x4000>;
					addr = <0x10040200 0x10040600 0x10040800 0x10040804 0x10040808 0x1004080C 0x10040810 0x10040814 0x10040848 0x1004084C
						0x10040850 0x10040C00 0x10040C04 0x10040D04 0x10040D08 0x10040D0C 0x10041800 0x10041804 0x10041808 0x1004180C
						0x10041810 0x10041814 0x10041848 0x1004184C 0x10041850 0x10041C00 0x10041C04 0x10041C08 0x10041C0C 0x10041C10
						0x10041C14 0x10041C18 0x10041C1C 0x10041C48 0x10041C4C 0x10041C50 0x10042000 0x10042004 0x10042008 0x1004200C
						0x10042010 0x1004240C 0x10042410 0x10042414 0x10042418 0x1004241C 0x10042420 0x10042424 0x10042428 0x1004242C
						0x10042430 0x10042434 0x10042438 0x1004243C 0x10042440 0x10042444 0x10042448 0x1004244C 0x10042450 0x10042454
						0x10042458 0x1004245C 0x10042460 0x10042464 0x10042468 0x1004246C 0x10042470 0x10042474 0x10042484 0x10042488
						0xFFFFFFFF>;
			};

			sfr-dump-smc0 {
					reg = <0x10800000 0x100>;
					addr = <0x1080004C 0xFFFFFFFF>;
			};

			sfr-dump-smc1 {
					reg = <0x10900000 0x100>;
					addr = <0x1090004C 0xFFFFFFFF>;
			};

			sfr-dump-smc2 {
					reg = <0x10A00000 0x100>;
					addr = <0x10A0004C 0xFFFFFFFF>;
			};

			sfr-dump-smc3 {
					reg = <0x10B00000 0x100>;
					addr = <0x10B0004C 0xFFFFFFFF>;
			};


		};
	};
};
